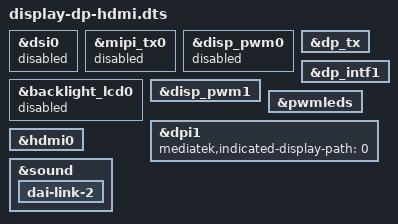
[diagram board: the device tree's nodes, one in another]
/dts-v1/;
/plugin/;

/ {
	fragment@0 {
		target = <&dsi0>;
		__overlay__ {
			status = "disabled";
		};
	};

	fragment@1 {
		target = <&mipi_tx0>;
		__overlay__ {
			status = "disabled";
		};
	};

	fragment@2 {
		target = <&disp_pwm0>;
		__overlay__ {
			status = "disabled";
		};
	};

	fragment@3 {
		target = <&backlight_lcd0>;
		__overlay__ {
			status = "disabled";
		};
	};

	fragment@4 {
		target = <&dp_tx>;
		__overlay__ {
			status = "okay";
		};
	};

	fragment@5 {
		target = <&dp_intf1>;
		__overlay__ {
			status = "okay";
		};
	};

	fragment@6 {
		target = <&disp_pwm1>;
		__overlay__ {
			status = "okay";
		};
	};

	fragment@7 {
		target = <&pwmleds>;
		__overlay__ {
			status = "okay";
		};
	};

	fragment@8 {
		target = <&dpi1>;
		__overlay__ {
			status = "okay";
			mediatek,indicated-display-path = <0>;
		};
	};

	fragment@9 {
		target = <&hdmi0>;
		__overlay__ {
			status = "okay";
		};
	};

	fragment@10 {
		target = <&sound>;
		__overlay__ {
			dai-link-2 {
				status = "okay";
			};
		};
	};
};
